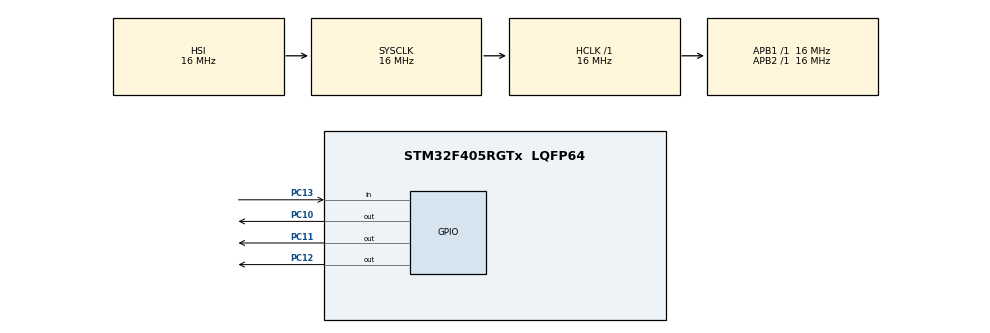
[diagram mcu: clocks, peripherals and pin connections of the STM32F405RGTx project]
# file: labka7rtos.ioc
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FREERTOS.Tasks01=bttask,32,128,StartDefaultTask,Default,NULL,Dynamic,NULL,NULL;ledtask1,24,128,StartTask02,Default,NULL,Dynamic,NULL,NULL;ledtask2,24,128,StartTask03,Default,NULL,Dynamic,NULL,NULL;ledtask3,24,128,StartTask04,Default,NULL,Dynamic,NULL,NULL
FREERTOS.configUSE_NEWLIB_REENTRANT=1
Mcu.Family=STM32F4
Mcu.Name=STM32F405RGTx
Mcu.Package=LQFP64
NVIC.PriorityGroup=NVIC_PRIORITYGROUP_4
NVIC.TIM6_DAC_IRQn=true\:15\:0\:false\:false\:true\:false\:false\:true\:true
NVIC.TimeBase=TIM6_DAC_IRQn
NVIC.TimeBaseIP=TIM6
PC10.Signal=GPIO_Output
PC11.Signal=GPIO_Output
PC12.Signal=GPIO_Output
PC13-ANTI_TAMP.GPIO_PuPd=GPIO_PULLDOWN
PC13-ANTI_TAMP.Signal=GPIO_Input
ProjectManager.HeapSize=0x200
ProjectManager.StackSize=0x400
ProjectManager.TargetToolchain=STM32CubeIDE
RCC.AHBFreq_Value=16000000
RCC.APB1Freq_Value=16000000
RCC.APB2Freq_Value=16000000
RCC.CortexFreq_Value=16000000
RCC.HSE_VALUE=25000000
RCC.HSI_VALUE=16000000
RCC.LSE_VALUE=32768
RCC.SYSCLKFreq_VALUE=16000000
RCC.VCOOutputFreq_Value=192000000
VP_FREERTOS_VS_CMSIS_V2.Mode=CMSIS_V2
VP_SYS_VS_tim6.Mode=TIM6
board=custom

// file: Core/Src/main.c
/* USER CODE BEGIN Header */
/**
  ******************************************************************************
  * @file           : main.c
  * @brief          : Main program body
  ******************************************************************************
  * @attention
  *
  * Copyright (c) 2026 STMicroelectronics.
  * All rights reserved.
  *
  * This software is licensed under terms that can be found in the LICENSE file
  * in the root directory of this software component.
  * If no LICENSE file comes with this software, it is provided AS-IS.
  *
  ******************************************************************************
  */
/* USER CODE END Header */
#include "main.h"
#include "cmsis_os.h"

/* Definitions for bttask */
osThreadId_t bttaskHandle;
const osThreadAttr_t bttask_attributes = {
  .name = "bttask",
  .stack_size = 128 * 4,
  .priority = (osPriority_t) osPriorityAboveNormal,
};
/* Definitions for ledtask1 */
osThreadId_t ledtask1Handle;
const osThreadAttr_t ledtask1_attributes = {
  .name = "ledtask1",
  .stack_size = 128 * 4,
  .priority = (osPriority_t) osPriorityNormal,
};
/* Definitions for ledtask2 */
osThreadId_t ledtask2Handle;
const osThreadAttr_t ledtask2_attributes = {
  .name = "ledtask2",
  .stack_size = 128 * 4,
  .priority = (osPriority_t) osPriorityNormal,
};
/* Definitions for ledtask3 */
osThreadId_t ledtask3Handle;
const osThreadAttr_t ledtask3_attributes = {
  .name = "ledtask3",
  .stack_size = 128 * 4,
  .priority = (osPriority_t) osPriorityNormal,
};
/* USER CODE BEGIN PV */
uint32_t led1_period = 500;
/* USER CODE END PV */

void SystemClock_Config(void);
static void MX_GPIO_Init(void);
void StartDefaultTask(void *argument);
void StartTask02(void *argument);
void StartTask03(void *argument);
void StartTask04(void *argument);

int main(void)
{

  /* MCU Configuration--------------------------------------------------------*/

  /* Reset of all peripherals, Initializes the Flash interface and the Systick. */
  HAL_Init();

  /* Configure the system clock */
  SystemClock_Config();

  /* Initialize all configured peripherals */
  MX_GPIO_Init();

  /* Init scheduler */
  osKernelInitialize();

  /* Create the thread(s) */
  /* creation of bttask */
  bttaskHandle = osThreadNew(StartDefaultTask, NULL, &bttask_attributes);

  /* creation of ledtask1 */
  ledtask1Handle = osThreadNew(StartTask02, NULL, &ledtask1_attributes);

  /* creation of ledtask2 */
  ledtask2Handle = osThreadNew(StartTask03, NULL, &ledtask2_attributes);

  /* creation of ledtask3 */
  ledtask3Handle = osThreadNew(StartTask04, NULL, &ledtask3_attributes);

  /* Start scheduler */
  osKernelStart();

  /* We should never get here as control is now taken by the scheduler */

  /* Infinite loop */
  while (1)
  {

  }
}

void SystemClock_Config(void)
{
  RCC_OscInitTypeDef RCC_OscInitStruct = {0};
  RCC_ClkInitTypeDef RCC_ClkInitStruct = {0};

  /** Configure the main internal regulator output voltage
  */
  __HAL_RCC_PWR_CLK_ENABLE();
  __HAL_PWR_VOLTAGESCALING_CONFIG(PWR_REGULATOR_VOLTAGE_SCALE1);

  /** Initializes the RCC Oscillators according to the specified parameters
  * in the RCC_OscInitTypeDef structure.
  */
  RCC_OscInitStruct.OscillatorType = RCC_OSCILLATORTYPE_HSI;
  RCC_OscInitStruct.HSIState = RCC_HSI_ON;
  RCC_OscInitStruct.HSICalibrationValue = RCC_HSICALIBRATION_DEFAULT;
  RCC_OscInitStruct.PLL.PLLState = RCC_PLL_NONE;
  if (HAL_RCC_OscConfig(&RCC_OscInitStruct) != HAL_OK)
  {
    Error_Handler();
  }

  /** Initializes the CPU, AHB and APB buses clocks
  */
  RCC_ClkInitStruct.ClockType = RCC_CLOCKTYPE_HCLK|RCC_CLOCKTYPE_SYSCLK
                              |RCC_CLOCKTYPE_PCLK1|RCC_CLOCKTYPE_PCLK2;
  RCC_ClkInitStruct.SYSCLKSource = RCC_SYSCLKSOURCE_HSI;
  RCC_ClkInitStruct.AHBCLKDivider = RCC_SYSCLK_DIV1;
  RCC_ClkInitStruct.APB1CLKDivider = RCC_HCLK_DIV1;
  RCC_ClkInitStruct.APB2CLKDivider = RCC_HCLK_DIV1;

  if (HAL_RCC_ClockConfig(&RCC_ClkInitStruct, FLASH_LATENCY_0) != HAL_OK)
  {
    Error_Handler();
  }
}

static void MX_GPIO_Init(void)
{
  GPIO_InitTypeDef GPIO_InitStruct = {0};

  /* GPIO Ports Clock Enable */
  __HAL_RCC_GPIOC_CLK_ENABLE();

  /*Configure GPIO pin Output Level */
  HAL_GPIO_WritePin(GPIOC, GPIO_PIN_10|GPIO_PIN_11|GPIO_PIN_12, GPIO_PIN_RESET);

  /*Configure GPIO pin : PC13 */
  GPIO_InitStruct.Pin = GPIO_PIN_13;
  GPIO_InitStruct.Mode = GPIO_MODE_INPUT;
  GPIO_InitStruct.Pull = GPIO_PULLDOWN;
  HAL_GPIO_Init(GPIOC, &GPIO_InitStruct);

  /*Configure GPIO pins : PC10 PC11 PC12 */
  GPIO_InitStruct.Pin = GPIO_PIN_10|GPIO_PIN_11|GPIO_PIN_12;
  GPIO_InitStruct.Mode = GPIO_MODE_OUTPUT_PP;
  GPIO_InitStruct.Pull = GPIO_NOPULL;
  GPIO_InitStruct.Speed = GPIO_SPEED_FREQ_LOW;
  HAL_GPIO_Init(GPIOC, &GPIO_InitStruct);

}

void StartDefaultTask(void *argument)
{
  /* USER CODE BEGIN 5 */
  /* Infinite loop */
  for(;;)
  {
	 if (HAL_GPIO_ReadPin(GPIOC,GPIO_PIN_13)==GPIO_PIN_RESET){
		 led1_period=800;
	 }else{
		 led1_period=500;
	 }
    osDelay(50);
  }
  /* USER CODE END 5 */
}

void StartTask02(void *argument)
{
  /* USER CODE BEGIN StartTask02 */
  /* Infinite loop */
  for(;;)
  {
	  HAL_GPIO_TogglePin(GPIOC,GPIO_PIN_10);
    osDelay(led1_period);
  }
  /* USER CODE END StartTask02 */
}

void StartTask03(void *argument)
{
  /* USER CODE BEGIN StartTask03 */
  /* Infinite loop */
  for(;;)
  {
    HAL_GPIO_TogglePin(GPIOC,GPIO_PIN_11);
    osDelay(400);
  }
  /* USER CODE END StartTask03 */
}

void StartTask04(void *argument)
{
  /* USER CODE BEGIN StartTask04 */
  /* Infinite loop */
  for(;;)
  {
	  HAL_GPIO_TogglePin(GPIOC,GPIO_PIN_12);
    osDelay(150);
  }
  /* USER CODE END StartTask04 */
}

void HAL_TIM_PeriodElapsedCallback(TIM_HandleTypeDef *htim)
{
  if (htim->Instance == TIM6)
  {
    HAL_IncTick();
  }
}

void Error_Handler(void)
{
  __disable_irq();
  while (1)
  {
  }
}
